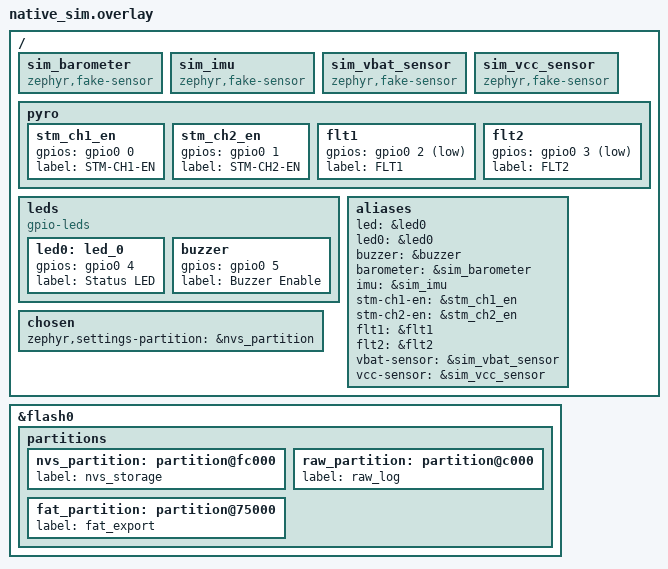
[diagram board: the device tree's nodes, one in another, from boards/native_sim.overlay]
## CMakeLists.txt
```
cmake_minimum_required(VERSION 3.13.1)
find_package(Zephyr REQUIRED HINTS $ENV{ZEPHYR_BASE})

project(marshal LANGUAGES C)

target_include_directories(app PRIVATE include)
target_sources(app PRIVATE src/main.cpp src/device_runtime.cpp src/pd_sink.c src/sim_pipe_reader.c
                            src/sim_flight_replay.cpp src/usb_support.cpp)
```

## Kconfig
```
# Copyright (c) 2024 Aaron Chan
# SPDX-License-Identifier: Apache-2.0
#
# This file is the application Kconfig entry point. All application Kconfig
# options can be defined here or included via other application Kconfig files.
# You can browse these options using the west targets menuconfig (terminal) or
# guiconfig (GUI).

menu "Zephyr"
source "Kconfig.zephyr"
endmenu

module = APP
module-str = APP
source "subsys/logging/Kconfig.template.log_config"

menu "Marshal"

config VBAT_MIN_MV
	int "Minimum VBAT voltage (mV)"
	default 3300
	range 2500 16000
	help
		Minimum battery voltage threshold, in millivolts, used by VoltageMonitor::isVbatOk().

endmenu
```

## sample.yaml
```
# This file is provided so that the application can be compiled using Twister,
# the Zephyr testing tool. In this file, multiple combinations can be specified,
# so that you can easily test all of them locally or in CI.
sample:
  description: Marshal Flight Computer
  name: marshal
common:
  build_only: true
  integration_platforms:
    - marshal
tests:
  app.default: {}
  app.debug:
    extra_overlay_confs:
      - debug.conf
```

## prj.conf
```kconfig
# Copyright (c) 2026 Aaron Chan
# SPDX-License-Identifier: Apache-2.0

#
# Core modules
#
CONFIG_CORE=y
CONFIG_CORE_SENSORS=y
CONFIG_CORE_IO=y
CONFIG_CORE_FLIGHT=y
CONFIG_CORE_FLIGHT_LOGGER=y
CONFIG_CORE_SETTINGS=y
CONFIG_CORE_SETTINGS_FLIGHT_COMPUTER=y
CONFIG_CORE_PYRO=y

#
# C++
#
CONFIG_CPP=y
CONFIG_REQUIRES_FULL_LIBCPP=y
CONFIG_STD_CPP23=y

#
# Serial / console
#
CONFIG_SERIAL=y
CONFIG_CONSOLE=y
CONFIG_PRINTK=y
CONFIG_UART_CONSOLE=y
CONFIG_UART_INTERRUPT_DRIVEN=y

#
# Logging
#
CONFIG_LOG=y
CONFIG_LOG_BACKEND_UART=y
CONFIG_CBPRINTF_FP_SUPPORT=y
CONFIG_LOG_MODE_DEFERRED=y
CONFIG_LOG_PROCESS_THREAD_STACK_SIZE=3072
CONFIG_LOG_BUFFER_SIZE=8192
CONFIG_EXTRA_EXCEPTION_INFO=y

#
# Shell
#
CONFIG_SHELL=y
CONFIG_SHELL_BACKEND_SERIAL=y
CONFIG_SHELL_STACK_SIZE=8192
CONFIG_SHELL_LOG_BACKEND=y
CONFIG_SHELL_CMDS=y
CONFIG_SHELL_HISTORY=y
CONFIG_SHELL_TAB=y
CONFIG_SHELL_WILDCARD=y
CONFIG_SHELL_METAKEYS=y
CONFIG_SHELL_VT100_COMMANDS=y
CONFIG_SHELL_CMDS_SELECT=y
CONFIG_SHELL_GETOPT=y
CONFIG_SHELL_HELP=y
CONFIG_SHELL_STATS=y
CONFIG_DEVICE_SHELL=n
CONFIG_DATE_SHELL=n
CONFIG_DEVMEM_SHELL=n
CONFIG_APP_VERSION_SHELL=n
CONFIG_KERNEL_SHELL=n
CONFIG_THREAD_MONITOR=n
CONFIG_THREAD_STACK_INFO=n
CONFIG_LOG_RUNTIME_FILTERING=n
CONFIG_HWINFO=y
CONFIG_HWINFO_SHELL=y

#
# USB
#
CONFIG_USB_DEVICE_STACK=n
CONFIG_USB_DEVICE_STACK_NEXT=y
CONFIG_USBC_STACK=y
CONFIG_USBC_CSM_SINK_ONLY=y
CONFIG_USBC_THREAD_PRIORITY=10
CONFIG_USBC_TCPC_SHELL=y
CONFIG_USBD_CDC_ACM_CLASS=y
CONFIG_USBD_CDC_ACM_LOG_LEVEL_OFF=y
CONFIG_USBD_MSC_CLASS=y
CONFIG_USBD_BOS_SUPPORT=n
CONFIG_USBD_VREQ_SUPPORT=n
CONFIG_USBD_THREAD_STACK_SIZE=2048
CONFIG_USBD_MSC_STACK_SIZE=2048

#
# Flash / storage
#
CONFIG_FLASH=y
CONFIG_FLASH_MAP=y
CONFIG_FLASH_PAGE_LAYOUT=y
CONFIG_MPU_ALLOW_FLASH_WRITE=y
CONFIG_SPI_NOR_FLASH_LAYOUT_PAGE_SIZE=4096

#
# Disk
#
CONFIG_DISK_ACCESS=y
CONFIG_DISK_DRIVERS=y
CONFIG_DISK_DRIVER_FLASH=y

#
# Filesystem
#
CONFIG_FILE_SYSTEM=y
CONFIG_FILE_SYSTEM_MKFS=y
CONFIG_FAT_FILESYSTEM_ELM=y
CONFIG_FS_FATFS_MOUNT_MKFS=n

#
# Settings / NVS
#
CONFIG_NVS=y
CONFIG_SETTINGS=y
CONFIG_SETTINGS_NVS=y
CONFIG_SETTINGS_NVS_SECTOR_SIZE_MULT=1
CONFIG_SETTINGS_NVS_SECTOR_COUNT=4

#
# Drivers
#
CONFIG_ADC=y
CONFIG_ADC_STM32_DMA=y
CONFIG_SENSOR=y
CONFIG_MS56XX=y
CONFIG_COUNTER=y
CONFIG_SPI_STM32_DMA=y

#
# Stack / heap
#
CONFIG_MAIN_STACK_SIZE=8192
CONFIG_ISR_STACK_SIZE=4096
CONFIG_SYSTEM_WORKQUEUE_STACK_SIZE=6144
CONFIG_HEAP_MEM_POOL_SIZE=8192

#
# Debugging
#
CONFIG_ASSERT=y
CONFIG_ASSERT_VERBOSE=n
CONFIG_INIT_STACKS=n
CONFIG_STACK_SENTINEL=n
CONFIG_THREAD_NAME=y
CONFIG_THREAD_ANALYZER=n
CONFIG_THREAD_ANALYZER_AUTO=n
```

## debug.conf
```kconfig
# Copyright (c) 2024 Aaron Chan
# SPDX-License-Identifier: Apache-2.0
#
# This is a Kconfig fragment which can be used to enable debug-related options
# in the application. See the README for more details.

# compiler
CONFIG_DEBUG_OPTIMIZATIONS=y

# logging
CONFIG_LOG=y
CONFIG_APP_LOG_LEVEL_DBG=y
```

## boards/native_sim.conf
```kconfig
CONFIG_USB_DEVICE_STACK=n
CONFIG_USB_DEVICE_STACK_NEXT=n
CONFIG_SPI=n
CONFIG_SPI_NOR=n
CONFIG_ADC=n

# Enable emulated sensor framework
CONFIG_SENSOR=y

# Logging goes to native console
CONFIG_CONSOLE=y

# NVS on emulated flash
CONFIG_FLASH=y
CONFIG_FLASH_MAP=y
CONFIG_NVS=y

# GPIO for pyro/LED stubs
CONFIG_GPIO=y

# Added for native_sim Unix domain socket reader
CONFIG_NETWORKING=y
CONFIG_NET_DRIVERS=y
CONFIG_NET_SOCKETS=y
CONFIG_NET_SOCKETS_OFFLOAD=y
CONFIG_NET_NATIVE_OFFLOADED_SOCKETS=y
CONFIG_ETH_NATIVE_TAP=n
CONFIG_POSIX_API=y

# Keep simulator build minimal: no FAT/disk plumbing required for compile smoke tests
CONFIG_FILE_SYSTEM=n
CONFIG_FAT_FILESYSTEM_ELM=n
CONFIG_FS_FATFS_MKFS=n
CONFIG_FILE_SYSTEM_MKFS=n
CONFIG_DISK_ACCESS=n
CONFIG_DISK_DRIVERS=n
CONFIG_DISK_DRIVER_FLASH=n

# Silence board-irrelevant warnings inherited from prj.conf
CONFIG_MS56XX=n
CONFIG_SHELL_BACKEND_SERIAL=n
CONFIG_THREAD_ANALYZER=n
```

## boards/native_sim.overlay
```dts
/ {
	sim_barometer: sim_barometer {
		compatible = "zephyr,fake-sensor";
		status = "okay";
	};

	sim_imu: sim_imu {
		compatible = "zephyr,fake-sensor";
		status = "okay";
	};

	sim_vbat_sensor: sim_vbat_sensor {
		compatible = "zephyr,fake-sensor";
		status = "okay";
	};

	sim_vcc_sensor: sim_vcc_sensor {
		compatible = "zephyr,fake-sensor";
		status = "okay";
	};

	pyro: pyro {
		stm_ch1_en: stm_ch1_en {
			gpios = <&gpio0 0 GPIO_ACTIVE_HIGH>;
			label = "STM-CH1-EN";
		};

		stm_ch2_en: stm_ch2_en {
			gpios = <&gpio0 1 GPIO_ACTIVE_HIGH>;
			label = "STM-CH2-EN";
		};

		flt1: flt1 {
			gpios = <&gpio0 2 GPIO_ACTIVE_LOW>;
			label = "FLT1";
		};

		flt2: flt2 {
			gpios = <&gpio0 3 GPIO_ACTIVE_LOW>;
			label = "FLT2";
		};
	};

	leds {
		compatible = "gpio-leds";

		led0: led_0 {
			gpios = <&gpio0 4 GPIO_ACTIVE_HIGH>;
			label = "Status LED";
		};

		buzzer: buzzer {
			gpios = <&gpio0 5 GPIO_ACTIVE_HIGH>;
			label = "Buzzer Enable";
		};
	};

	aliases {
		led = &led0;
		led0 = &led0;
		buzzer = &buzzer;
		barometer = &sim_barometer;
		imu = &sim_imu;
		stm-ch1-en = &stm_ch1_en;
		stm-ch2-en = &stm_ch2_en;
		flt1 = &flt1;
		flt2 = &flt2;
		vbat-sensor = &sim_vbat_sensor;
		vcc-sensor = &sim_vcc_sensor;
	};

	chosen {
		zephyr,settings-partition = &nvs_partition;
	};
};

&flash0 {
	partitions {
		nvs_partition: partition@fc000 {
			label = "nvs_storage";
		};

		raw_partition: partition@c000 {
			label = "raw_log";
		};

		fat_partition: partition@75000 {
			label = "fat_export";
		};
	};
};
```

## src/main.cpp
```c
/*
 * Copyright (c) 2026 Aaron Chan
 * SPDX-License-Identifier: Apache-2.0
 */

#include <core/settings/FlightComputerSettings.h>
#include <marshal/device_runtime.h>
#include <zephyr/logging/log.h>

LOG_MODULE_REGISTER(marshal, LOG_LEVEL_INF);

int main() {
    int ret = FlightComputerSettings::load();
    if (ret != 0) {
        LOG_ERR("Failed to load settings: %d", ret);
    }

    ret = marshal::initRuntime();
    if (ret != 0) {
        LOG_ERR("Runtime init completed with error: %d", ret);
    }

    marshal::startRuntimeThreads();
    marshal::runStatusLoop();

    return 0;
}
```

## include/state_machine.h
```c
#pragma once

#include <stdint.h>
#include <zephyr/kernel.h>

#include "core/GnssReceiver.h"
#include "core/LoraTransceiver.h"

class StateMachine {
public:
#ifdef CONFIG_LICENSED_FREQUENCY
    explicit StateMachine(uint8_t nodeId, const float frequencyMHz = 903.0, const char callsign[6] = "");
#else
    explicit StateMachine(uint8_t nodeId, const float frequencyMHz = 903.0);
#endif
    void handleTxTimer();

    int run();

private:
    enum class State { Transmitter, Receiver };

    void enterTransmitter();
    void enterReceiver();
    void exitReceiver();
    void transitionTo(State target);
    int checkForTransition();

#ifdef CONFIG_LICENSED_FREQUENCY
    const char* callsign;
#endif
    LoraTransceiver lora;
    GnssReceiver gnssReceiver;
    k_timer txTimer{};
    uint8_t nodeId{};
    int lastPinSate{-1};
    State currentState{State::Transmitter};
};
```

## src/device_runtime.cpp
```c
/*
 * Copyright (c) 2026 Aaron Chan
 * SPDX-License-Identifier: Apache-2.0
 */

#include <cmath>
#include <core/flight/FlightStateMachine.h>
#include <core/flight_logger/FlightExporter.h>
#include <core/flight_logger/FlightLogger.h>
#include <core/io/Buzzer.h>
#include <core/io/Led.h>
#include <core/pyro/PyroController.h>
#include <core/sensors/Barometer.h>
#include <core/sensors/Imu.h>
#include <core/sensors/VoltageMonitor.h>
#include <core/settings/FlightComputerSettings.h>
#include <cstdlib>
#include <marshal/device_runtime.h>
#include <marshal/sim_flight_replay.h>
#include <marshal/usb_support.h>
#include <zephyr/device.h>
#include <zephyr/drivers/hwinfo.h>
#include <zephyr/drivers/gpio.h>
#include <zephyr/kernel.h>
#include <zephyr/logging/log.h>
#include <zephyr/storage/flash_map.h>
#ifdef CONFIG_SHELL
#include <zephyr/shell/shell.h>
#endif

#ifdef CONFIG_BOARD_NATIVE_SIM
#include <posix_board_if.h>
extern "C" void sim_pipe_reader_start(void);
#endif

LOG_MODULE_DECLARE(marshal);

namespace marshal {

static gpio_dt_spec statusLedSpec = GPIO_DT_SPEC_GET(DT_ALIAS(led), gpios);
static gpio_dt_spec buzzerSpec = GPIO_DT_SPEC_GET(DT_ALIAS(buzzer), gpios);
static Led statusLed(&statusLedSpec);
static Buzzer buzzer(&buzzerSpec);

#if !defined(CONFIG_BOARD_NATIVE_SIM)
static Barometer barometer(DEVICE_DT_GET(DT_ALIAS(barometer)));
static Imu imu(DEVICE_DT_GET(DT_ALIAS(imu)));
static VoltageMonitor voltageMonitor(DEVICE_DT_GET(DT_ALIAS(vbat_sensor)), DEVICE_DT_GET(DT_ALIAS(vcc_sensor)));
static gpio_dt_spec drogueEnSpec{DEVICE_DT_GET(DT_NODELABEL(gpiob)), 9, GPIO_ACTIVE_HIGH};
static gpio_dt_spec mainEnSpec{DEVICE_DT_GET(DT_NODELABEL(gpiob)), 7, GPIO_ACTIVE_HIGH};
static gpio_dt_spec drogueFltSpec{DEVICE_DT_GET(DT_NODELABEL(gpioc)), 13, GPIO_ACTIVE_LOW};
static gpio_dt_spec mainFltSpec{DEVICE_DT_GET(DT_NODELABEL(gpioa)), 4, GPIO_ACTIVE_LOW};
static PyroController droguePyro(drogueEnSpec, drogueFltSpec);
static PyroController mainPyro(mainEnSpec, mainFltSpec);
static bool armed = false;
static FlightLogger* flightLogger = nullptr;
static FlightExporter* flightExporter = nullptr;
static FlightStateMachine* flightStateMachine = nullptr;
static float padAltitudeM = 0.0f;
static float currentAltitudeM = 0.0f;
static bool apogeeSeen = false;
static uint32_t apogeeTimeMs = 0U;
static bool drogueDeployIssued = false;
static bool mainDeployIssued = false;
static constexpr uint16_t kBatteryPresentMarginMv = 150U;
static constexpr uint32_t kResetCauseReportDelayMs = 2000U;
#if defined(CONFIG_HWINFO)
static uint32_t pendingResetCause = 0U;
static bool pendingResetCauseValid = false;
static k_work_delayable resetCauseReportWork;
#endif

#define BARO_STACK_SIZE 1024
#define BARO_PRIORITY   4
K_THREAD_STACK_DEFINE(baroStack, BARO_STACK_SIZE);
static k_thread baroThread;

#define VOLTAGE_STACK_SIZE 512
#define VOLTAGE_PRIORITY   10
K_THREAD_STACK_DEFINE(voltageStack, VOLTAGE_STACK_SIZE);
static k_thread voltageThread;

static constexpr uint16_t kImuLoopRateHz = 100;
static constexpr uint16_t kBaroLoopRateHz = 100;
static constexpr uint32_t kPyroFireDurationMs = 25U;

static float pressureKPaToAltitudeM(float pressureKPa) {
    return 44330.0f * (1.0f - std::pow(pressureKPa / 101.325f, 1.0f / 5.255f));
}

static uint32_t sensorValueMilli(const sensor_value& value) {
    return static_cast<uint32_t>(value.val1) * 1000U + static_cast<uint32_t>(value.val2 / 1000);
}

static void logPyroAction(uint8_t channel, FlightLog::PyroAction action) {
    if (flightLogger != nullptr && flightLogger->isRecording()) {
        flightLogger->logPyroEvent(channel, action, 0);
    }
}

static void resetFlightActions() {
    apogeeSeen = false;
    apogeeTimeMs = 0U;
    drogueDeployIssued = false;
    mainDeployIssued = false;
}

static int ensurePyrosArmed();

static void requestPyroDeploy(PyroController& controller, uint8_t channel, const char* reason) {
    // Log FIRE intent before pulling the trigger. PYRO_EVENT force-flushes the page on
    // pickup (FlightLogger writerLoop), and the brief sleep gives the writer thread a
    // scheduling window to get the record onto flash before a brownout can eat it.
    logPyroAction(channel, FlightLog::PyroAction::FIRE);
    k_msleep(10);

    const int ret = controller.fire(kPyroFireDurationMs);
    if (ret != 0) {
        LOG_ERR("Pyro channel %u fire failed during %s: %d", channel, reason, ret);
        logPyroAction(channel, FlightLog::PyroAction::FAULT);
        return;
    }

    LOG_WRN("Pyro channel %u fired for %u ms (%s)", channel, kPyroFireDurationMs, reason);
}

static void maybeRunDeployments() {
    if (!armed || !apogeeSeen) {
        return;
    }

    const auto mode = FlightComputerSettings::deployMode();
    const uint32_t now = k_uptime_get_32();
    const bool apogeeDelayElapsed = (now - apogeeTimeMs) >= FlightComputerSettings::apogeeDelayMs();

    switch (mode) {
        case FlightComputerSettings::DeployMode::DUAL_DEPLOY:
            if (!drogueDeployIssued && apogeeDelayElapsed) {
                requestPyroDeploy(droguePyro, 1, "apogee drogue");
                drogueDeployIssued = true;
            }

            if (!mainDeployIssued && currentAltitudeM <= FlightComputerSettings::mainDeployAltM()) {
                requestPyroDeploy(mainPyro, 2, "main deploy altitude");
                mainDeployIssued = true;
            }
            break;

        case FlightComputerSettings::DeployMode::DROGUE_ONLY:
            if (!drogueDeployIssued && apogeeDelayElapsed) {
                requestPyroDeploy(droguePyro, 1, "apogee drogue");
                drogueDeployIssued = true;
            }
            break;

        case FlightComputerSettings::DeployMode::MAIN_ONLY:
            if (!mainDeployIssued) {
                requestPyroDeploy(mainPyro, 2, "main-only apogee deploy");
                mainDeployIssued = true;
            }
            break;
    }
}

static void handleStateChange(FlightState oldState, FlightState newState) {
    if (newState == FlightState::BOOST && flightLogger != nullptr && !flightLogger->isRecording()) {
        resetFlightActions();
        const uint32_t id = FlightComputerSettings::incrementFlightCounter();
        const int ret = flightLogger->startFlight(id, kImuLoopRateHz, kBaroLoopRateHz);
        if (ret != 0) {
            LOG_ERR("Failed to start flight logging for flight %u: %d", id, ret);
        } else {
            LOG_INF("Flight %u logging started", id);
        }
    }

    if (newState == FlightState::BOOST) {
        const int ret = ensurePyrosArmed();
        if (ret != 0) {
            LOG_ERR("Pyro arming failed at boost detect: %d", ret);
        }
    }

    if (flightLogger != nullptr && flightLogger->isRecording()) {
        flightLogger->logStateChange(static_cast<uint8_t>(oldState), static_cast<uint8_t>(newState));
    }

    if (newState == FlightState::APOGEE) {
        apogeeSeen = true;
        apogeeTimeMs = k_uptime_get_32();
        LOG_INF("Apogee detected, deployment timer started");
    }

    if (newState == FlightState::LANDED) {
        const int drogueDisarmRet = droguePyro.disarm();
        if (drogueDisarmRet == 0) {
            logPyroAction(1, FlightLog::PyroAction::DISARM);
        }

        const int mainDisarmRet = mainPyro.disarm();
        if (mainDisarmRet == 0) {
            logPyroAction(2, FlightLog::PyroAction::DISARM);
        }

        if (flightLogger != nullptr && flightLogger->isRecording()) {
            flightLogger->endFlight();
        }
    }
}

static void baroThreadEntry(void*, void*, void*) {
    BaroSample latestBaroSample = barometer.sample();
    uint32_t loopCount = 0U;

    while (true) {
        const ImuSample imuSample = imu.sample();
        if ((loopCount % (kImuLoopRateHz / kBaroLoopRateHz)) == 0U) {
            latestBaroSample = barometer.sample();
        }

        const FlightState state = flightStateMachine->update(imuSample, latestBaroSample);

        if (flightLogger != nullptr && flightLogger->isRecording()) {
            flightLogger->logImu(imuSample);
            if ((loopCount % (kImuLoopRateHz / kBaroLoopRateHz)) == 0U) {
                flightLogger->logBaro(latestBaroSample);
            }
        }

        const uint32_t pressureMilliKpa = sensorValueMilli(latestBaroSample.pressure);
        const float absoluteAltitudeM = pressureKPaToAltitudeM(static_cast<float>(pressureMilliKpa) / 1000.0f);
        currentAltitudeM = absoluteAltitudeM - padAltitudeM;

        if (state == FlightState::PAD) {
            padAltitudeM = absoluteAltitudeM;
            currentAltitudeM = 0.0f;
        } else if (currentAltitudeM < 0.0f) {
            currentAltitudeM = 0.0f;
        }

        maybeRunDeployments();

        // LOG_INF("Flight state=%u pressure=%u.%03u kPa altitude=%u.%03u m agl=%d.%03d m temp=%d.%03d C",
        //         static_cast<unsigned>(state), pressureMilliKpa / 1000, pressureMilliKpa % 1000, altitudeMm / 1000,
        //         altitudeMm % 1000, aglMilliM / 1000, std::abs(aglMilliM % 1000), tempMilliC / 1000,
        //         std::abs(tempMilliC % 1000));

        ++loopCount;
        k_sleep(K_MSEC(1000 / kImuLoopRateHz));
    }
}

static void voltageThreadEntry(void*, void*, void*) {
    while (true) {
        voltageMonitor.sample();
        const uint16_t vbatMv = static_cast<uint16_t>(voltageMonitor.vbatMv());
        const uint16_t vccMv = static_cast<uint16_t>(voltageMonitor.vccMv());

        if (flightLogger != nullptr && flightLogger->isRecording()) {
            flightLogger->logVoltage(vbatMv, vccMv, 0, 0);
        }

        // LOG_INF("Voltage: VBAT=%u mV, VCC=%u mV", vbatMv, vccMv);

        k_sleep(K_MSEC(1000));
    }
}

static int sampleVoltages(uint16_t& vbatMv, uint16_t& vccMv) {
    // Zephyr adc_stm32's set_channel_differential_mode early-return check is broken on
    // STM32G4 (compares raw DIFSEL bit against CALFACT-domain constants), so every
    // adc_channel_setup after init returns -EBUSY. The init-time sample populates
    // VoltageMonitor's cached values; fall back to those on -EBUSY.
    const int ret = voltageMonitor.sample();
    vbatMv = static_cast<uint16_t>(voltageMonitor.vbatMv());
    vccMv = static_cast<uint16_t>(voltageMonitor.vccMv());
    if (ret == 0) {
        return 0;
    }
    if (ret == -EBUSY && vbatMv > 0) {
        LOG_WRN("ADC busy, using cached VBAT=%u mV VCC=%u mV", vbatMv, vccMv);
        return 0;
    }
    LOG_ERR("Voltage sample failed: %d", ret);
    return ret;
}

static int checkBatteryVoltage() {
    uint16_t vbatMv = 0U;
    uint16_t vccMv = 0U;
    int ret = sampleVoltages(vbatMv, vccMv);
    if (ret != 0) {
        return ret;
    }

    const uint16_t threshold = FlightComputerSettings::minBatteryMv();
    if (vbatMv < threshold) {
        LOG_ERR("Battery voltage %u mV below lockout threshold %u mV - NOT ARMING", vbatMv, threshold);
        return -EIO;
    }

    if (vbatMv <= static_cast<uint16_t>(vccMv + kBatteryPresentMarginMv)) {
        LOG_ERR("Battery not present on pyro rail: VBAT=%u mV VCC=%u mV (need VBAT > VCC + %u mV)", vbatMv,
                vccMv, kBatteryPresentMarginMv);
        return -ENODEV;
    }

    LOG_INF("Battery voltage OK for pyro: VBAT=%u mV, VCC=%u mV (threshold %u mV)", vbatMv, vccMv, threshold);
    return 0;
}

#if defined(CONFIG_HWINFO)
static const char* resetCauseToString(uint32_t cause) {
    switch (cause) {
        case RESET_PIN:
            return "pin";
        case RESET_SOFTWARE:
            return "software";
        case RESET_BROWNOUT:
            return "brownout";
        case RESET_POR:
            return "power-on reset";
        case RESET_WATCHDOG:
            return "watchdog";
        case RESET_DEBUG:
            return "debug";
        case RESET_SECURITY:
            return "security";
        case RESET_LOW_POWER_WAKE:
            return "low power wake-up";
        case RESET_CPU_LOCKUP:
            return "CPU lockup";
        case RESET_PARITY:
            return "parity error";
        case RESET_PLL:
            return "PLL error";
        case RESET_CLOCK:
            return "clock";
        case RESET_HARDWARE:
            return "hardware";
        case RESET_USER:
            return "user";
        case RESET_TEMPERATURE:
            return "temperature";
        case RESET_BOOTLOADER:
            return "bootloader";
        case RESET_FLASH:
            return "flash";
        default:
            return "unknown";
    }
}

static void reportResetCause(struct k_work* work) {
    ARG_UNUSED(work);

    if (!pendingResetCauseValid || pendingResetCause == 0U) {
        return;
    }

    LOG_WRN("Previous reset cause flags: 0x%08x", pendingResetCause);
    for (uint32_t causeMask = 1U; causeMask != 0U; causeMask <<= 1U) {
        if ((pendingResetCause & causeMask) != 0U) {
            LOG_WRN("Previous reset cause: %s", resetCauseToString(causeMask));
        }
    }
}

static void captureResetCause() {
    uint32_t cause = 0U;
    const int ret = hwinfo_get_reset_cause(&cause);
    if (ret == -ENOSYS) {
        return;
    }

    if (ret != 0) {
        LOG_ERR("Failed to read reset cause: %d", ret);
        return;
    }

    pendingResetCause = cause;
    pendingResetCauseValid = true;

    const int clearRet = hwinfo_clear_reset_cause();
    if (clearRet != 0 && clearRet != -ENOSYS) {
        LOG_ERR("Failed to clear reset cause: %d", clearRet);
    }
}
#endif

static int ensurePyrosArmed() {
    if (armed) {
        return 0;
    }

    const int batteryRet = checkBatteryVoltage();
    if (batteryRet != 0) {
        return batteryRet;
    }

    int ret = droguePyro.arm();
    if (ret != 0) {
        LOG_ERR("Drogue pyro arm failed: %d", ret);
        logPyroAction(1, FlightLog::PyroAction::FAULT);
        return ret;
    }
    logPyroAction(1, FlightLog::PyroAction::ARM);

    ret = mainPyro.arm();
    if (ret != 0) {
        LOG_ERR("Main pyro arm failed: %d", ret);
        logPyroAction(2, FlightLog::PyroAction::FAULT);
        return ret;
    }
    logPyroAction(2, FlightLog::PyroAction::ARM);

    armed = true;
    return 0;
}

#ifdef CONFIG_SHELL
static int cmdTestLog(const struct shell* sh, size_t argc, char** argv) {
    ARG_UNUSED(argc);

    if (flightLogger == nullptr || flightExporter == nullptr) {
        shell_error(sh, "Logger/exporter not initialized");
        return -ENODEV;
    }

    if (flightLogger->isRecording()) {
        shell_error(sh, "Flight logging already in progress");
        return -EBUSY;
    }

    char* end = nullptr;
    const unsigned long durationSeconds = strtoul(argv[1], &end, 10);
    if (argv[1][0] == '\0' || end == nullptr || *end != '\0' || durationSeconds == 0UL) {
        shell_error(sh, "Usage: test log <seconds>");
        return -EINVAL;
    }

    const uint32_t flightId = FlightComputerSettings::incrementFlightCounter();
    int ret = flightLogger->startFlight(flightId, kImuLoopRateHz, kBaroLoopRateHz);
    if (ret != 0) {
        shell_error(sh, "Failed to start logging: %d", ret);
        return ret;
    }

    shell_print(sh, "Recording flight %u for %lu second(s)...", flightId, durationSeconds);
    k_sleep(K_SECONDS(durationSeconds));
    flightLogger->endFlight();
    k_sleep(K_MSEC(100));

    ret = flightExporter->scanFlights();
    if (ret < 0) {
        shell_error(sh, "Recorded flight %u but scan failed: %d", flightId, ret);
        return ret;
    }

    ret = flightExporter->exportLatest();
    if (ret == 0) {
        shell_print(sh, "Flight %u recorded and exported to the FAT partition.", flightId);
        return 0;
    }

    shell_error(sh, "Flight %u recorded but export failed: %d", flightId, ret);
    return ret;
}

static int cmdTestDeploy(const struct shell* sh, size_t argc, char** argv) {
    ARG_UNUSED(argc);
    ARG_UNUSED(argv);

    if (flightLogger == nullptr) {
        shell_error(sh, "Logger not initialized");
        return -ENODEV;
    }

    int ret = ensurePyrosArmed();
    if (ret != 0) {
        shell_error(sh, "Failed to arm pyros: %d", ret);
        return ret;
    }

    uint16_t vbatMv = 0U;
    uint16_t vccMv = 0U;
    ret = sampleVoltages(vbatMv, vccMv);
    if (ret == 0) {
        shell_print(sh, "Pre-fire voltages: VBAT=%u mV VCC=%u mV", vbatMv, vccMv);
    }

    // Start a flight recording so the pre-fire FIRE records actually hit flash
    // and survive a brownout mid-pulse. Route both channels through requestPyroDeploy
    // so the shell test exercises exactly the same path a real flight takes.
    const uint32_t flightId = FlightComputerSettings::incrementFlightCounter();
    ret = flightLogger->startFlight(flightId, kImuLoopRateHz, kBaroLoopRateHz);
    if (ret != 0) {
        shell_error(sh, "Failed to start logging for test: %d", ret);
        return ret;
    }
    shell_print(sh, "Recording test flight %u", flightId);

    shell_print(sh, "Firing drogue pyro for %u ms", kPyroFireDurationMs);
    requestPyroDeploy(droguePyro, 1, "test deploy drogue");

    k_sleep(K_MSEC(100));

    shell_print(sh, "Firing main pyro for %u ms", kPyroFireDurationMs);
    requestPyroDeploy(mainPyro, 2, "test deploy main");

    flightLogger->endFlight();
    k_sleep(K_MSEC(100));

    shell_print(sh, "Pyro test complete");
    return 0;
}

SHELL_STATIC_SUBCMD_SET_CREATE(
    subTest, SHELL_CMD_ARG(log, NULL, "Record live data for N seconds, then export latest flight", cmdTestLog, 2, 0),
    SHELL_CMD(deploy, NULL, "Arm and fire both pyro channels", cmdTestDeploy), SHELL_SUBCMD_SET_END);

SHELL_CMD_REGISTER(test, &subTest, "Marshal test helpers", NULL);
#endif
#endif

int initRuntime() {
    int ret = statusLed.init();
    if (ret != 0) {
        LOG_ERR("Status LED init failed: %d", ret);
    }

    ret = buzzer.init();
    if (ret != 0) {
        LOG_ERR("Buzzer init failed: %d", ret);
    }

#if !defined(CONFIG_BOARD_NATIVE_SIM)
#if defined(CONFIG_HWINFO)
    k_work_init_delayable(&resetCauseReportWork, reportResetCause);
    captureResetCause();
#endif

    static const flash_area* rawFa = nullptr;
    static const flash_area* fatFa = nullptr;
    ret = flash_area_open(PARTITION_ID(raw_partition), &rawFa);
    if (ret != 0) {
        LOG_ERR("Failed to open raw partition: %d", ret);
    }

    ret = flash_area_open(PARTITION_ID(fat_partition), &fatFa);
    if (ret != 0) {
        LOG_ERR("Failed to open FAT partition: %d", ret);
    }

    static FlightLogger logger(rawFa);
    static FlightExporter exporter(rawFa, fatFa);
    flightLogger = &logger;
    flightExporter = &exporter;

    if (rawFa != nullptr) {
        ret = flightLogger->init();
        if (ret != 0) {
            LOG_ERR("Flight logger init failed: %d", ret);
        }
        flightLoggerShellRegister(flightLogger);
    }

    if (rawFa != nullptr && fatFa != nullptr) {
        ret = exporter.init();
        if (ret != 0) {
            LOG_ERR("Flight exporter init failed: %d", ret);
        } else {
            flightExporterShellRegister(&exporter);
        }
    }

    ret = initUsb();
    if (ret != 0) {
        LOG_ERR("USB init failed: %d", ret);
    }
#if defined(CONFIG_HWINFO)
    if (pendingResetCauseValid && pendingResetCause != 0U) {
        k_work_schedule(&resetCauseReportWork, K_MSEC(kResetCauseReportDelayMs));
    }
#endif

    ret = barometer.init();
    if (ret != 0) {
        LOG_ERR("Barometer init failed: %d", ret);
    }

    ret = imu.init(nullptr);
    if (ret != 0) {
        LOG_ERR("IMU init failed: %d", ret);
    }

    ret = voltageMonitor.init();
    if (ret != 0) {
        LOG_ERR("Voltage monitor init failed: %d", ret);
    }

    ret = droguePyro.init();
    if (ret != 0) {
        LOG_ERR("Drogue pyro init failed: %d", ret);
    }

    ret = mainPyro.init();
    if (ret != 0) {
        LOG_ERR("Main pyro init failed: %d", ret);
    }

    static FlightStateMachine fsm(barometer, imu);
    flightStateMachine = &fsm;
    flightStateMachine->onStateChange(handleStateChange);
#else
    if (sim::flightReplayRequested()) {
        LOG_INF("native_sim mode: flight replay enabled");
    } else {
        LOG_INF("native_sim mode: waiting for socket-fed sim sensor data");
    }
#endif

    return 0;
}

void startRuntimeThreads() {
#if !defined(CONFIG_BOARD_NATIVE_SIM)
    k_thread_create(&baroThread, baroStack, BARO_STACK_SIZE, baroThreadEntry, nullptr, nullptr, nullptr, BARO_PRIORITY,
                    0, K_NO_WAIT);

    k_thread_create(&voltageThread, voltageStack, VOLTAGE_STACK_SIZE, voltageThreadEntry, nullptr, nullptr, nullptr,
                    VOLTAGE_PRIORITY, 0, K_NO_WAIT);
#else
    if (sim::flightReplayRequested()) {
        const int ret = sim::startFlightReplay();
        if (ret != 0) {
            LOG_ERR("Failed to start native flight replay: %d", ret);
            posix_exit(1);
        }
    } else {
        sim_pipe_reader_start();
    }
#endif
}

void runStatusLoop() {
    // buzzer.beep(3000);
    while (true) {
        statusLed.toggle();
        k_msleep(1000);
    }
}

} // namespace marshal
```

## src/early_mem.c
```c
#include <stddef.h>
#include <stdint.h>
#include <zephyr/linker/section_tags.h>

__boot_func void arch_early_memset(void *dst, int c, size_t n)
{
	volatile uint8_t *p = (volatile uint8_t *)dst;

	while (n-- > 0U) {
		*p++ = (uint8_t)c;
	}
}

__boot_func void arch_early_memcpy(void *dst, const void *src, size_t n)
{
	volatile uint8_t *d = (volatile uint8_t *)dst;
	const volatile uint8_t *s = (const volatile uint8_t *)src;

	while (n-- > 0U) {
		*d++ = *s++;
	}
}
```

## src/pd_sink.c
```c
/*
 * Copyright (c) 2026 Aaron Chan
 * SPDX-License-Identifier: Apache-2.0
 */

#include <zephyr/device.h>
#include <zephyr/devicetree.h>
#include <zephyr/init.h>
#include <zephyr/kernel.h>
#include <zephyr/logging/log.h>
#include <zephyr/usb_c/usbc.h>

LOG_MODULE_REGISTER(marshal_pd, LOG_LEVEL_INF);

#define USBC_PORT0_NODE DT_ALIAS(usbc_port0)

#if DT_NODE_HAS_STATUS(USBC_PORT0_NODE, okay)

static struct marshal_pd_port_data {
    uint32_t snk_caps[DT_PROP_LEN(USBC_PORT0_NODE, sink_pdos)];
    int snk_cap_cnt;
    uint32_t src_caps[PDO_MAX_DATA_OBJECTS];
    int src_cap_cnt;
    atomic_t ps_ready;
} port0_data = {
    .snk_caps = DT_PROP(USBC_PORT0_NODE, sink_pdos),
    .snk_cap_cnt = DT_PROP_LEN(USBC_PORT0_NODE, sink_pdos),
    .src_caps = {0},
    .src_cap_cnt = 0,
    .ps_ready = 0,
};

static uint32_t build_rdo(void) {
    union pd_rdo rdo = {
        .raw_value = 0,
    };

    rdo.fixed.min_or_max_operating_current = PD_CONVERT_MA_TO_FIXED_PDO_CURRENT(500);
    rdo.fixed.operating_current = PD_CONVERT_MA_TO_FIXED_PDO_CURRENT(500);
    rdo.fixed.unchunked_ext_msg_supported = 0;
    rdo.fixed.no_usb_suspend = 1;
    rdo.fixed.usb_comm_capable = 1;
    rdo.fixed.cap_mismatch = 0;
    rdo.fixed.giveback = 0;
    rdo.fixed.object_pos = 1;

    return rdo.raw_value;
}

static int port0_policy_cb_get_snk_cap(const struct device *dev, uint32_t **pdos, int *num_pdos) {
    struct marshal_pd_port_data *dpm_data = usbc_get_dpm_data(dev);

    *pdos = dpm_data->snk_caps;
    *num_pdos = dpm_data->snk_cap_cnt;

    return 0;
}

static void port0_policy_cb_set_src_cap(const struct device *dev, const uint32_t *pdos, const int num_pdos) {
    struct marshal_pd_port_data *dpm_data = usbc_get_dpm_data(dev);
    int num = MIN(num_pdos, PDO_MAX_DATA_OBJECTS);

    for (int i = 0; i < num; ++i) {
        dpm_data->src_caps[i] = pdos[i];
    }

    dpm_data->src_cap_cnt = num;
}

static uint32_t port0_policy_cb_get_rdo(const struct device *dev) {
    ARG_UNUSED(dev);
    return build_rdo();
}

static bool port0_policy_check(const struct device *dev, const enum usbc_policy_check_t policy_check) {
    ARG_UNUSED(dev);

    switch (policy_check) {
        case CHECK_POWER_ROLE_SWAP:
            return false;
        case CHECK_DATA_ROLE_SWAP_TO_DFP:
            return false;
        case CHECK_DATA_ROLE_SWAP_TO_UFP:
            return true;
        case CHECK_SNK_AT_DEFAULT_LEVEL:
            return true;
        default:
            return false;
    }
}

static void port0_notify(const struct device *dev, const enum usbc_policy_notify_t policy_notify) {
    struct marshal_pd_port_data *dpm_data = usbc_get_dpm_data(dev);

    switch (policy_notify) {
        case POWER_CHANGE_0A0:
            LOG_INF("USB-C sink current: 0A");
            break;
        case POWER_CHANGE_DEF:
            LOG_INF("USB-C sink current: default");
            break;
        case POWER_CHANGE_1A5:
            LOG_INF("USB-C sink current: 1.5A");
            break;
        case POWER_CHANGE_3A0:
            LOG_INF("USB-C sink current: 3.0A");
            break;
        case TRANSITION_PS:
            atomic_set_bit(&dpm_data->ps_ready, 0);
            break;
        case PD_CONNECTED:
            LOG_INF("USB-C PD contract established");
            break;
        case PORT_PARTNER_NOT_RESPONSIVE:
            LOG_INF("USB-C partner is not PD capable");
            break;
        default:
            break;
    }
}

static int marshal_pd_sink_init(void) {
    const struct device *usbc_port0 = DEVICE_DT_GET(USBC_PORT0_NODE);

    if (!device_is_ready(usbc_port0)) {
        LOG_ERR("USB-C port device not ready");
        return -ENODEV;
    }

    port0_data.ps_ready = ATOMIC_INIT(0);

    usbc_set_policy_cb_check(usbc_port0, port0_policy_check);
    usbc_set_policy_cb_notify(usbc_port0, port0_notify);
    usbc_set_policy_cb_get_snk_cap(usbc_port0, port0_policy_cb_get_snk_cap);
    usbc_set_policy_cb_set_src_cap(usbc_port0, port0_policy_cb_set_src_cap);
    usbc_set_policy_cb_get_rdo(usbc_port0, port0_policy_cb_get_rdo);
    usbc_set_dpm_data(usbc_port0, &port0_data);
    usbc_start(usbc_port0);

    LOG_INF("USB-C PD sink started");
    return 0;
}

SYS_INIT(marshal_pd_sink_init, APPLICATION, 0);

#endif
```

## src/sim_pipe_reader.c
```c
// SPDX-License-Identifier: Apache-2.0

#include <zephyr/kernel.h>
#include <zephyr/logging/log.h>

LOG_MODULE_REGISTER(sim_pipe_reader);

#ifdef CONFIG_BOARD_NATIVE_SIM

#include <core/sim/sim_pipe_protocol.h>
#include <core/sim/sim_sensor_state.h>
#include <errno.h>
#include <stdbool.h>
#include <stddef.h>
#include <stdint.h>
#include <stdio.h>
#include <string.h>
#include <sys/socket.h>
#include <sys/un.h>
#include <unistd.h>
#include <zephyr/drivers/sensor.h>

#define SIM_PIPE_READER_STACK_SIZE 2048
#define SIM_PIPE_READER_PRIORITY   5
#define SIM_PIPE_SOCKET_PATH       "/tmp/marshal_sim.sock"

K_THREAD_STACK_DEFINE(sim_pipe_reader_stack, SIM_PIPE_READER_STACK_SIZE);
static struct k_thread sim_pipe_reader_thread;
static bool sim_pipe_reader_started;

static ssize_t sim_pipe_read_exact(int fd, void *buffer, size_t size) {
    uint8_t *cursor = buffer;
    size_t total = 0U;

    while (total < size) {
        const ssize_t bytes_read = recv(fd, cursor + total, size - total, 0);
        if (bytes_read > 0) {
            total += (size_t) bytes_read;
            continue;
        }

        if (bytes_read < 0 && errno == EINTR) {
            continue;
        }

        break;
    }

    return (ssize_t) total;
}

static void sim_pipe_update_state(const struct SimFrame *frame) {
    k_mutex_lock(&g_sim_sensor_mutex, K_FOREVER);

    (void) sensor_value_from_float(&g_sim_sensor_state.accel_x, frame->accel_x_mps2);
    (void) sensor_value_from_float(&g_sim_sensor_state.accel_y, frame->accel_y_mps2);
    (void) sensor_value_from_float(&g_sim_sensor_state.accel_z, frame->accel_z_mps2);
    (void) sensor_value_from_float(&g_sim_sensor_state.gyro_x, frame->gyro_x_rads);
    (void) sensor_value_from_float(&g_sim_sensor_state.gyro_y, frame->gyro_y_rads);
    (void) sensor_value_from_float(&g_sim_sensor_state.gyro_z, frame->gyro_z_rads);
    (void) sensor_value_from_float(&g_sim_sensor_state.pressure, frame->pressure_pa);
    (void) sensor_value_from_float(&g_sim_sensor_state.temperature, frame->temp_c);

    k_mutex_unlock(&g_sim_sensor_mutex);
}

static void sim_pipe_reader_thread_entry(void *arg1, void *arg2, void *arg3) {
    ARG_UNUSED(arg1);
    ARG_UNUSED(arg2);
    ARG_UNUSED(arg3);

    struct sockaddr_un address;
    const int backlog = 1;

    const int server_fd = socket(AF_UNIX, SOCK_STREAM, 0);
    if (server_fd < 0) {
        LOG_ERR("socket(%s) failed: %d", SIM_PIPE_SOCKET_PATH, errno);
        return;
    }

    (void) unlink(SIM_PIPE_SOCKET_PATH);

    memset(&address, 0, sizeof(address));
    address.sun_family = AF_UNIX;
    strncpy(address.sun_path, SIM_PIPE_SOCKET_PATH, sizeof(address.sun_path) - 1U);

    if (bind(server_fd, (struct sockaddr *) &address, sizeof(address)) < 0) {
        LOG_ERR("bind(%s) failed: %d", SIM_PIPE_SOCKET_PATH, errno);
        (void) close(server_fd);
        return;
    }

    if (listen(server_fd, backlog) < 0) {
        LOG_ERR("listen(%s) failed: %d", SIM_PIPE_SOCKET_PATH, errno);
        (void) close(server_fd);
        (void) unlink(SIM_PIPE_SOCKET_PATH);
        return;
    }

    LOG_INF("sim sensor socket ready at %s", SIM_PIPE_SOCKET_PATH);

    while (true) {
        const int client_fd = accept(server_fd, NULL, NULL);
        if (client_fd < 0) {
            if (errno == EINTR) {
                continue;
            }

            LOG_ERR("accept(%s) failed: %d", SIM_PIPE_SOCKET_PATH, errno);
            k_msleep(100);
            continue;
        }

        while (true) {
            struct SimFrame frame;
            const ssize_t bytes_read = sim_pipe_read_exact(client_fd, &frame, sizeof(frame));

            if (bytes_read != (ssize_t) sizeof(frame)) {
                LOG_INF("sim stream client disconnected");
                break;
            }

            if (frame.magic != SIM_FRAME_MAGIC) {
                LOG_WRN("dropping sim frame with bad magic: 0x%04x", frame.magic);
                continue;
            }

            if (frame.version != SIM_FRAME_VERSION) {
                LOG_WRN("dropping sim frame with unsupported version: %u", frame.version);
                continue;
            }

            sim_pipe_update_state(&frame);
        }

        (void) close(client_fd);
    }
}

void sim_pipe_reader_start(void) {
    if (sim_pipe_reader_started) {
        return;
    }

    sim_pipe_reader_started = true;

    k_tid_t tid =
        k_thread_create(&sim_pipe_reader_thread, sim_pipe_reader_stack, K_THREAD_STACK_SIZEOF(sim_pipe_reader_stack),
                        sim_pipe_reader_thread_entry, NULL, NULL, NULL, SIM_PIPE_READER_PRIORITY, 0, K_NO_WAIT);
    k_thread_name_set(tid, "sim_pipe_reader");
}

#else

void sim_pipe_reader_start(void) {}

#endif
```

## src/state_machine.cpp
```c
#include "state_machine.h"

#include <zephyr/drivers/gnss.h>
#include <zephyr/drivers/gpio.h>
#include <zephyr/kernel.h>
#include <zephyr/logging/log.h>

static constexpr int TRANSMITTER_LOGIC_LEVEL = 0;
static constexpr int TRANSMITTER_LED_LEVEL = 0;

static constexpr int RECEIVER_LOGIC_LEVEL = 1;
static constexpr int RECEIVER_LED_LEVEL = 1;

LOG_MODULE_REGISTER(state_machine);

static const gpio_dt_spec dip0 = GPIO_DT_SPEC_GET(DT_ALIAS(dip0), gpios);
static const gpio_dt_spec led = GPIO_DT_SPEC_GET(DT_ALIAS(led0), gpios);

static void txTimerCallback(struct k_timer* timer) {
    if (auto* sm = static_cast<StateMachine*>(k_timer_user_data_get(timer))) {
        sm->handleTxTimer();
    }
}

#ifdef CONFIG_LICENSED_FREQUENCY
StateMachine::StateMachine(uint8_t nodeId, const float frequencyMHz, const char* callsign) :  callsign(callsign), lora(nodeId, frequencyMHz), nodeId(nodeId) {
    k_timer_init(&txTimer, txTimerCallback, nullptr);
    k_timer_user_data_set(&txTimer, this);
    lora.setCallsign(callsign);

#ifdef CONFIG_DEFAULT_RECEIVE_MODE
    currentState = State::Receiver;
    enterReceiver();
#else
    currentState = State::Transmitter;
    enterTransmitter();
#endif

    setGnssReciever(&gnssReceiver);
}

#else

StateMachine::StateMachine(const uint8_t nodeId, const float frequencyMhz) :  lora(nodeId, frequencyMhz), nodeId(nodeId) {
    k_timer_init(&txTimer, txTimerCallback, nullptr);
    k_timer_user_data_set(&txTimer, this);

#ifdef CONFIG_DEFAULT_RECEIVE_MODE
    currentState = State::Receiver;
    enterReceiver();
#else
    currentState = State::Transmitter;
    enterTransmitter();
#endif

    setGnssReciever(&gnssReceiver);
}

#endif


void StateMachine::handleTxTimer() {
    if (gnssReceiver.isFixAcquired()) {
        lora.txGnssPayload(gnssReceiver.getLatestData());
    } else {
        lora.txNoFixPayload();
    }
}

int StateMachine::run() {
    return checkForTransition();
}

void StateMachine::enterTransmitter() {
    LOG_INF("Entering transmitter state");
    lora.setTx();

    gpio_pin_set_dt(&led, TRANSMITTER_LED_LEVEL);
    k_timer_start(&txTimer, K_SECONDS(5), K_SECONDS(5));
}

void StateMachine::enterReceiver() {
    LOG_INF("Entering receiver state");
    lora.setRx();
    gpio_pin_set_dt(&led, RECEIVER_LED_LEVEL);
    k_timer_stop(&txTimer);
    lora.awaitRxPacket();
}

void StateMachine::exitReceiver() {
    lora.awaitCancel();
}

void StateMachine::transitionTo(State target) {
    if (target == currentState) {
        return;
    }

    if (currentState == State::Receiver) {
        exitReceiver();
    }

    currentState = target;

    if (currentState == State::Transmitter) {
        enterTransmitter();
    } else {
        enterReceiver();
    }
}

int StateMachine::checkForTransition() {
    const int current_pin_state = gpio_pin_get_dt(&dip0);
    LOG_DBG("Pin state: %d", current_pin_state);

    if (current_pin_state < 0) {
        LOG_DBG("dip0 gpio read error (%d); ignoring transition check", current_pin_state);
        return 0;
    }

    if (lastPinSate != current_pin_state) {
        if (current_pin_state == TRANSMITTER_LOGIC_LEVEL) {
            transitionTo(State::Transmitter);
        } else if (current_pin_state == RECEIVER_LOGIC_LEVEL) {
            transitionTo(State::Receiver);
        }
    }

    lastPinSate = current_pin_state;

    return 0;
}
```

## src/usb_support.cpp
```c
/*
 * Copyright (c) 2026 Aaron Chan
 * SPDX-License-Identifier: Apache-2.0
 */

#include <marshal/usb_support.h>
#include <zephyr/device.h>

#if defined(CONFIG_USB_DEVICE_STACK_NEXT)
#include <zephyr/usb/usbd.h>
#endif
#if defined(CONFIG_USBD_MSC_CLASS)
#include <zephyr/usb/class/usbd_msc.h>
#endif

namespace marshal {

#if defined(CONFIG_USB_DEVICE_STACK_NEXT)
USBD_DEVICE_DEFINE(marshal_usbd, DEVICE_DT_GET(DT_NODELABEL(zephyr_udc0)), 0x0483, 0x5740);
USBD_DESC_LANG_DEFINE(marshal_lang);
USBD_DESC_MANUFACTURER_DEFINE(marshal_mfr, "Wild West Rocketry");
USBD_DESC_PRODUCT_DEFINE(marshal_product, "Marshal Flight Computer");
USBD_DESC_SERIAL_NUMBER_DEFINE(marshal_sn);
USBD_DESC_CONFIG_DEFINE(marshal_fs_cfg, "FS Config");
USBD_CONFIGURATION_DEFINE(marshal_fs_config, USB_SCD_SELF_POWERED, 125, &marshal_fs_cfg);

static void setUsbCodeTriple(enum usbd_speed speed) {
    if (IS_ENABLED(CONFIG_USBD_CDC_ACM_CLASS) || IS_ENABLED(CONFIG_USBD_MSC_CLASS)) {
        usbd_device_set_code_triple(&marshal_usbd, speed, USB_BCC_MISCELLANEOUS, 0x02, 0x01);
        return;
    }

    usbd_device_set_code_triple(&marshal_usbd, speed, 0, 0, 0);
}
#endif

#if defined(CONFIG_USBD_MSC_CLASS)
USBD_DEFINE_MSC_LUN(marshal, "marshal", "WWR", "Marshal", "1.00");
#endif

int initUsb() {
#if !defined(CONFIG_USB_DEVICE_STACK_NEXT)
    return 0;
#else
    int ret = usbd_add_descriptor(&marshal_usbd, &marshal_lang);
    if (ret != 0) {
        return ret;
    }

    ret = usbd_add_descriptor(&marshal_usbd, &marshal_mfr);
    if (ret != 0) {
        return ret;
    }

    ret = usbd_add_descriptor(&marshal_usbd, &marshal_product);
    if (ret != 0) {
        return ret;
    }

    ret = usbd_add_descriptor(&marshal_usbd, &marshal_sn);
    if (ret != 0) {
        return ret;
    }

    ret = usbd_add_configuration(&marshal_usbd, USBD_SPEED_FS, &marshal_fs_config);
    if (ret != 0) {
        return ret;
    }

    ret = usbd_register_all_classes(&marshal_usbd, USBD_SPEED_FS, 1, NULL);
    if (ret != 0) {
        return ret;
    }

    setUsbCodeTriple(USBD_SPEED_FS);

    ret = usbd_init(&marshal_usbd);
    if (ret != 0) {
        return ret;
    }

    return usbd_enable(&marshal_usbd);
#endif
}

} // namespace marshal
```
